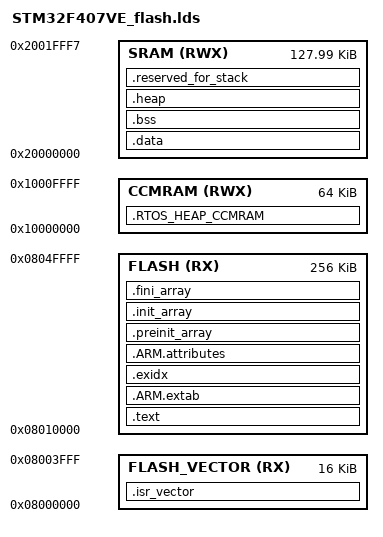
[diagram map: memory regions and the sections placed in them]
/* Generated by LinkerScriptGenerator [http://visualgdb.com/tools/LinkerScriptGenerator]
 * Target: STM32F407VG
 * The file is provided under the BSD license.
 */

ENTRY(Reset_Handler)

MEMORY
{
    FLASH_VECTOR (RX)   : ORIGIN = 0x08000000, LENGTH = 16K
	FLASH (RX)   : ORIGIN = 0x08010000, LENGTH = 256K
	SRAM (RWX)   : ORIGIN = 0x20000000, LENGTH = 0x0001FFF8
	CCMRAM (RWX) : ORIGIN = 0x10000000, LENGTH = 64K
}

_estack = 0x2001FFF8; /* При > 0x2001FFF8 вылет в HardFault после загрузчика */

SECTIONS
{

	.isr_vector :
	{
		. = ALIGN(4);
		KEEP(*(.isr_vector))
		. = ALIGN(4);
	} > FLASH_VECTOR

	.text :
	{
		. = ALIGN(4);
		_stext = .;      /* define a global symbols at start of code */

		*(.text)         /* .text sections (code) */                  
		*(.text*)        /* .text* sections (code) */                         
		*(.rodata)       /* .rodata sections (constants, strings, etc.) */              
		*(.rodata*)      /* .rodata* sections (constants, strings, etc.) */               
		*(.glue_7)       /* glue arm to thumb code */                              
		*(.glue_7t)      /* glue thumb to arm code */                         
		KEEP(*(.init))                    
		KEEP(*(.fini))                      
		. = ALIGN(4);
		_etext = .;      /* define a global symbols at end of code */ 

	} > FLASH

	.ARM.extab :
	{
		. = ALIGN(4);
		*(.ARM.extab)
		*(.gnu.linkonce.armextab.*)
		. = ALIGN(4);
	} > FLASH

	.exidx :
	{
		. = ALIGN(4);
		PROVIDE(__exidx_start = .);
		*(.ARM.exidx*)
		. = ALIGN(4);
		PROVIDE(__exidx_end = .);
	} > FLASH

	.ARM.attributes :
	{
		*(.ARM.attributes)
	} > FLASH

	.preinit_array :
	{
		PROVIDE(__preinit_array_start = .);
		KEEP(*(.preinit_array*))
		PROVIDE(__preinit_array_end = .);
	} > FLASH

	.init_array :
	{
		PROVIDE(__init_array_start = .);
		KEEP(*(SORT(.init_array.*)))
		KEEP(*(.init_array*))
		PROVIDE(__init_array_end = .);
	} > FLASH

	.fini_array :
	{
		PROVIDE(__fini_array_start = .);
		KEEP(*(.fini_array*))
		KEEP(*(SORT(.fini_array.*)))
		PROVIDE(__fini_array_end = .);
	} > FLASH

	. = ALIGN(4);
	_sidata = .;

	.data : AT(_sidata)
	{
		. = ALIGN(4);
		_sdata = .;             /* create a global symbol at data start */            

		PROVIDE(__data_start__ = _sdata);
		*(.data)                /* .data sections */                        
		*(.data*)               /* .data sections */                
		. = ALIGN(4);
		_edata = .;             /* define a global symbol at data end */           

		PROVIDE(__data_end__ = _edata);                   
	} > SRAM

	.bss :
	{
	/* This is used by the startup in order to initialize the .bss secion */
		. = ALIGN(4);
		_sbss = .;      /* define a global symbol at bss start */

		PROVIDE(__bss_start__ = _sbss);
		*(.bss)
		*(.bss*)
		*(COMMON)
		. = ALIGN(4);
		_ebss = .;      /* define a global symbol at bss end */

		PROVIDE(__bss_end__ = _ebss);
	} > SRAM

	PROVIDE(end = .);

	.heap (NOLOAD) :
	{
		. = ALIGN(4);
		PROVIDE(__heap_start__ = .);
		KEEP(*(.heap))
		. = ALIGN(4);
		PROVIDE(__heap_end__ = .);
	} > SRAM

	.reserved_for_stack (NOLOAD) :
	{
		. = ALIGN(4);
		PROVIDE(__reserved_for_stack_start__ = .);
		KEEP(*(.reserved_for_stack))
		. = ALIGN(4);
		PROVIDE(__reserved_for_stack_end__ = .);
	} > SRAM
	
	.RTOS_HEAP_CCMRAM (NOLOAD):
	{
	    KEEP(*(.RTOS_HEAP_CCMRAM))
	} > CCMRAM
}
